VERSION ""

NS_ :

BS_:

BU_:
VAL_TABLE_ pumpEnableEnum 3 "Don't Care" 2 "Reverse" 1 "Forward" 0 "Off" ;
VAL_TABLE_ enumKeySw 2 "ON" 1 "ACCESSORY" 0 "OFF" ;
VAL_TABLE_ enumPRNDL 6 "ReverseLow" 5 "DriveLow" 4 "DriveHigh" 3 "Neutral" 2 "ReverseHigh" 1 "Park" 0 "Fault" ;
VAL_TABLE_ enumPowerMode 8 "DiagnosticMode" 7 "Shutdown" 6 "Condition" 5 "Export" 4 "Drive" 3 "Charge" 2 "Idle" 1 "Initialize" 0 "FaultQuarantine" ;
VAL_TABLE_ enumVehicleState 10 "DiagnosticMode" 9 "Shutdown" 8 "ReverseLow" 7 "DriveLow" 6 "DriveHigh" 5 "Neutral" 4 "ReverseHigh" 3 "Park" 2 "Accessory" 1 "Initialize" 0 "FaultQuarantine" ;

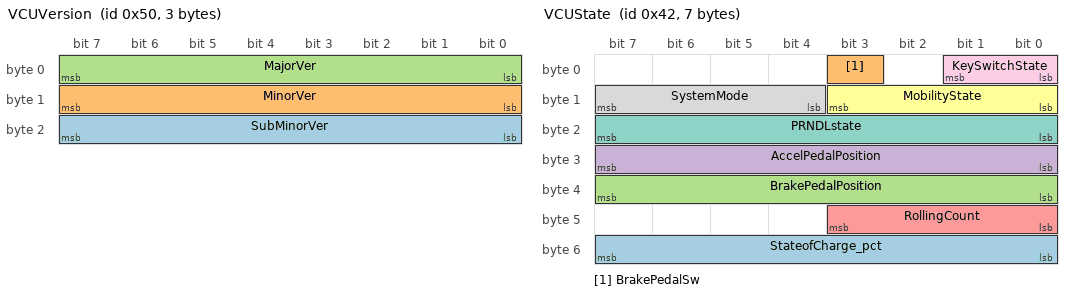
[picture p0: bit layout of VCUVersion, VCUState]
BO_ 80 VCUVersion: 3 Vector__XXX
 SG_ SubMinorVer : 16|8@1+ (1,0) [0|255] "" Vector__XXX
 SG_ MinorVer : 8|8@1+ (1,0) [0|255] "" Vector__XXX
 SG_ MajorVer : 0|8@1+ (1,0) [0|255] "" Vector__XXX

BO_ 66 VCUState: 7 Vector__XXX
 SG_ StateofCharge_pct : 48|8@1+ (1,0) [0|120] "" Vector__XXX
 SG_ BrakePedalSw : 3|1@1+ (1,0) [0|1] "" Vector__XXX
 SG_ BrakePedalPosition : 32|8@1+ (0.392156862745098,0) [0|100] "%" Vector__XXX
 SG_ AccelPedalPosition : 24|8@1+ (0.392156862745098,0) [0|100] "%" Vector__XXX
 SG_ RollingCount : 40|4@1+ (1,0) [0|15] "" Vector__XXX
 SG_ MobilityState : 8|4@1+ (1,0) [0|15] "" Vector__XXX
 SG_ PRNDLstate : 16|8@1+ (1,0) [0|0] "" Vector__XXX
 SG_ SystemMode : 12|4@1+ (1,0) [0|15] "" Vector__XXX
 SG_ KeySwitchState : 0|2@1+ (1,0) [0|3] "" Vector__XXX

CM_ "shared vcu bcm bus";
BA_DEF_  "BusType" STRING ;
BA_DEF_DEF_  "BusType" "CAN";
VAL_ 66 MobilityState 3 "ReverseMobility" 2 "Mobility" 1 "MobilityDisable" 0 "Park" ;
VAL_ 66 PRNDLstate 6 "Undefined" 4 "Drive" 3 "Neutral" 2 "Reverse" 1 "Park" 0 "Fault" ;
VAL_ 66 SystemMode 3 "Error" 2 "Shutdown" 1 "NormalOperation" 0 "Startup" ;
VAL_ 66 KeySwitchState 2 "ON" 1 "ACCESSORY" 0 "OFF" ;
